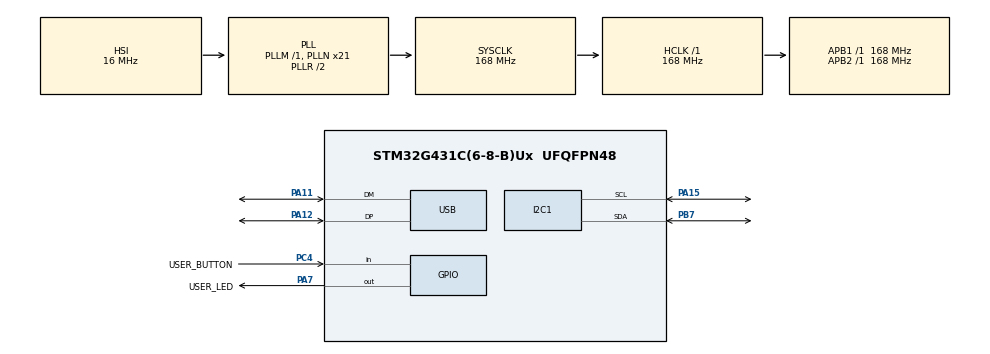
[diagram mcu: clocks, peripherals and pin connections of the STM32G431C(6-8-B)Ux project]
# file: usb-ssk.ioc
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Mcu.Family=STM32G4
Mcu.Name=STM32G431C(6-8-B)Ux
Mcu.Package=UFQFPN48
NVIC.PriorityGroup=NVIC_PRIORITYGROUP_4
NVIC.USB_LP_IRQn=true\:0\:0\:false\:false\:true\:false\:true\:true
PA11.Mode=Device
PA11.Signal=USB_DM
PA12.Mode=Device
PA12.Signal=USB_DP
PA13.Mode=Serial_Wire
PA13.Signal=SYS_JTMS-SWDIO
PA14.Mode=Serial_Wire
PA14.Signal=SYS_JTCK-SWCLK
PA15.Mode=I2C
PA15.Signal=I2C1_SCL
PA7.GPIO_Label=USER_LED
PA7.Signal=GPIO_Output
PB7.Mode=I2C
PB7.Signal=I2C1_SDA
PC4.GPIO_Label=USER_BUTTON
PC4.Signal=GPIO_Input
PF0-OSC_IN.Mode=HSE-External-Oscillator
PF0-OSC_IN.Signal=RCC_OSC_IN
PF1-OSC_OUT.Mode=HSE-External-Oscillator
PF1-OSC_OUT.Signal=RCC_OSC_OUT
ProjectManager.HeapSize=0x200
ProjectManager.StackSize=0x400
ProjectManager.TargetToolchain=STM32CubeIDE
RCC.ADC12Freq_Value=168000000
RCC.AHBFreq_Value=168000000
RCC.APB1Freq_Value=168000000
RCC.APB1TimFreq_Value=168000000
RCC.APB2Freq_Value=168000000
RCC.APB2TimFreq_Value=168000000
RCC.CK48CLockSelection=RCC_USBCLKSOURCE_HSI48
RCC.CortexFreq_Value=168000000
RCC.EXTERNAL_CLOCK_VALUE=12288000
RCC.HCLKFreq_Value=168000000
RCC.HSE_VALUE=12000000
RCC.HSI48_VALUE=48000000
RCC.HSI_VALUE=16000000
RCC.I2C1CLockSelection=RCC_I2C1CLKSOURCE_HSI
RCC.LSE_VALUE=32768
RCC.PLLN=21
RCC.SYSCLKFreq_VALUE=168000000
RCC.SYSCLKSource=RCC_SYSCLKSOURCE_PLLCLK
RCC.USBFreq_Value=48000000
RCC.VCOOutputFreq_Value=336000000
USB_DEVICE.CLASS_NAME_FS=CDC
USB_DEVICE.VirtualMode=Cdc
USB_DEVICE.VirtualModeFS=Cdc_FS
VP_SYS_VS_DBSignals.Mode=DisableDeadBatterySignals
VP_USB_DEVICE_VS_USB_DEVICE_CDC_FS.Mode=CDC_FS
board=custom

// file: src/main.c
#include "main.h"
#include "i2c.h"
#include "gpio.h"

#include "dfu.h"
#include "usb_device.h"
#include "usbd_cdc_if.h"
#include "iis2iclx_reg.h"

#define SENSOR_BUS hi2c1
#define BOOT_TIME 20 // ms

// Function prototypes
void SystemClock_Config(void);

//IIS2ICLX driver
static int32_t platform_write(void *handle, uint8_t reg, const uint8_t *bufp, uint16_t len);
static int32_t platform_read(void *handle, uint8_t reg, uint8_t *bufp, uint16_t len);

static int16_t data_raw[3];
static float data_formatted[3];
static uint8_t whoamI, rst;
static uint8_t tx_buffer[1000];

int main(void)
{
  HAL_Init();

  SystemClock_Config();

  MX_GPIO_Init();
  MX_I2C1_Init();
  MX_USB_Device_Init();

  stmdev_ctx_t dev_ctx;
  dev_ctx.write_reg = platform_write;
  dev_ctx.read_reg = platform_read;
  dev_ctx.mdelay = HAL_Delay;
  dev_ctx.handle = &SENSOR_BUS;

  HAL_Delay(BOOT_TIME);
  iis2iclx_bus_mode_set(&dev_ctx, IIS2ICLX_SEL_BY_HW);
  iis2iclx_device_id_get(&dev_ctx, &whoamI);

  if (whoamI != IIS2ICLX_ID)
    while (1)
    {
      HAL_GPIO_TogglePin(USER_LED_GPIO_Port, USER_LED_Pin);
      HAL_Delay(200);
    }

  iis2iclx_reset_set(&dev_ctx, PROPERTY_ENABLE);

  do
  {
    iis2iclx_reset_get(&dev_ctx, &rst);
  } while (rst);

  iis2iclx_block_data_update_set(&dev_ctx, PROPERTY_ENABLE);
  iis2iclx_xl_data_rate_set(&dev_ctx, IIS2ICLX_ODR_FSM_104Hz);
  iis2iclx_xl_full_scale_set(&dev_ctx, IIS2ICLX_500mg);

  /* Configure filtering chain(No aux interface)
   * Accelerometer - LPF1 + LPF2 path
   */
  iis2iclx_xl_hp_path_on_out_set(&dev_ctx, IIS2ICLX_LP_ODR_DIV_100);
  iis2iclx_xl_filter_lp2_set(&dev_ctx, PROPERTY_ENABLE);

  while (1)
  {
    uint8_t reg_acc, reg_temp;

    iis2iclx_xl_flag_data_ready_get(&dev_ctx, &reg_acc);
    iis2iclx_temp_flag_data_ready_get(&dev_ctx, &reg_temp);
    memset(data_raw, 0x00, 3 * sizeof(int16_t));

    if (reg_acc)
    {
      iis2iclx_acceleration_raw_get(&dev_ctx, &data_raw[0]);
      data_formatted[0] = iis2iclx_from_fs500mg_to_mg(data_raw[0]);
      data_formatted[1] = iis2iclx_from_fs500mg_to_mg(data_raw[1]);

    }

    if(reg_temp){
      iis2iclx_temperature_raw_get(&dev_ctx, &data_raw[0] + 2);
      data_formatted[2] = iis2iclx_from_lsb_to_celsius(data_raw[2]);

    }

    if(reg_acc || reg_temp){
      memset(tx_buffer, 0x00, 3 * sizeof(float_t));
      memcpy(&tx_buffer, &data_formatted, 3 * sizeof(float_t));
      CDC_Transmit_FS((uint8_t*)tx_buffer, 3 * sizeof(float_t));
    }

    if (HAL_GPIO_ReadPin(USER_BUTTON_GPIO_Port, USER_BUTTON_Pin) == GPIO_PIN_SET)
    {
      jump_to_bootloader();
    }
  }
}

static int32_t platform_write(void *handle, uint8_t reg, const uint8_t *bufp, uint16_t len)
{
  HAL_I2C_Mem_Write(handle, IIS2ICLX_I2C_ADD_L, reg, I2C_MEMADD_SIZE_8BIT, (uint8_t *)bufp, len, 1000);
  return 0;
}

static int32_t platform_read(void *handle, uint8_t reg, uint8_t *bufp, uint16_t len)
{
  HAL_I2C_Mem_Read(handle, IIS2ICLX_I2C_ADD_L, reg, I2C_MEMADD_SIZE_8BIT, bufp, len, 1000);
  return 0;
}

void SystemClock_Config(void)
{
  RCC_OscInitTypeDef RCC_OscInitStruct = {0};
  RCC_ClkInitTypeDef RCC_ClkInitStruct = {0};

  /** Configure the main internal regulator output voltage
   */
  HAL_PWREx_ControlVoltageScaling(PWR_REGULATOR_VOLTAGE_SCALE1_BOOST);

  /** Initializes the RCC Oscillators according to the specified parameters
   * in the RCC_OscInitTypeDef structure.
   */
  RCC_OscInitStruct.OscillatorType = RCC_OSCILLATORTYPE_HSI | RCC_OSCILLATORTYPE_HSI48;
  RCC_OscInitStruct.HSIState = RCC_HSI_ON;
  RCC_OscInitStruct.HSICalibrationValue = RCC_HSICALIBRATION_DEFAULT;
  RCC_OscInitStruct.HSI48State = RCC_HSI48_ON;
  RCC_OscInitStruct.PLL.PLLState = RCC_PLL_ON;
  RCC_OscInitStruct.PLL.PLLSource = RCC_PLLSOURCE_HSI;
  RCC_OscInitStruct.PLL.PLLM = RCC_PLLM_DIV1;
  RCC_OscInitStruct.PLL.PLLN = 21;
  RCC_OscInitStruct.PLL.PLLP = RCC_PLLP_DIV2;
  RCC_OscInitStruct.PLL.PLLQ = RCC_PLLQ_DIV2;
  RCC_OscInitStruct.PLL.PLLR = RCC_PLLR_DIV2;
  if (HAL_RCC_OscConfig(&RCC_OscInitStruct) != HAL_OK)
  {
    Error_Handler();
  }

  /** Initializes the CPU, AHB and APB buses clocks
   */
  RCC_ClkInitStruct.ClockType = RCC_CLOCKTYPE_HCLK | RCC_CLOCKTYPE_SYSCLK | RCC_CLOCKTYPE_PCLK1 | RCC_CLOCKTYPE_PCLK2;
  RCC_ClkInitStruct.SYSCLKSource = RCC_SYSCLKSOURCE_PLLCLK;
  RCC_ClkInitStruct.AHBCLKDivider = RCC_SYSCLK_DIV1;
  RCC_ClkInitStruct.APB1CLKDivider = RCC_HCLK_DIV1;
  RCC_ClkInitStruct.APB2CLKDivider = RCC_HCLK_DIV1;

  if (HAL_RCC_ClockConfig(&RCC_ClkInitStruct, FLASH_LATENCY_4) != HAL_OK)
  {
    Error_Handler();
  }
}

void Error_Handler(void)
{
  /* USER CODE BEGIN Error_Handler_Debug */
  /* User can add his own implementation to report the HAL error return state */
  __disable_irq();
  while (1)
  {
    HAL_GPIO_WritePin(USER_LED_GPIO_Port, USER_LED_Pin, GPIO_PIN_SET);
  }
  /* USER CODE END Error_Handler_Debug */
}
